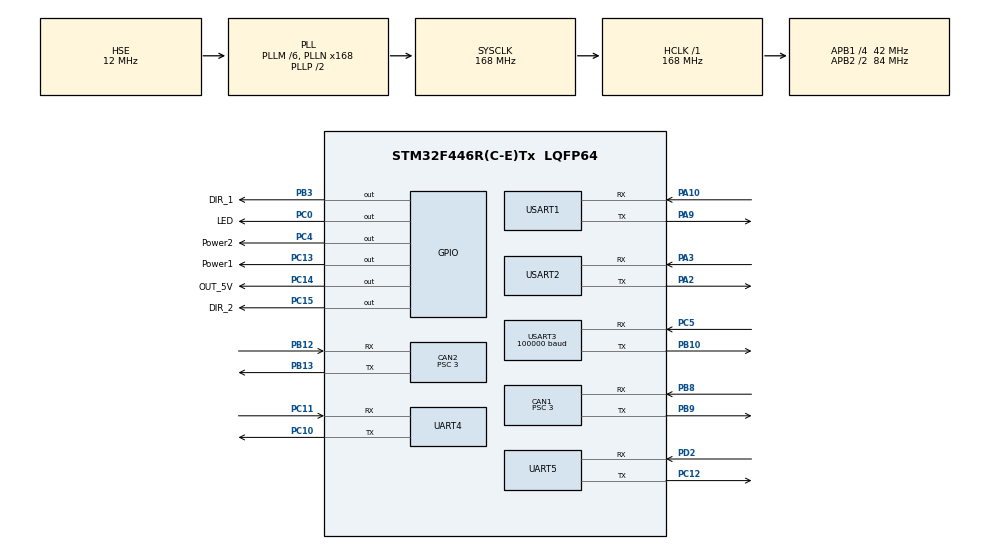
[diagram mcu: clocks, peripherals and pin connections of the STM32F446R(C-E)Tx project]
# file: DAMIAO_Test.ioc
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CAN1.BS1=CAN_BS1_10TQ
CAN1.BS2=CAN_BS2_3TQ
CAN1.CalculateBaudRate=1000000
CAN1.CalculateTimeBit=1000
CAN1.CalculateTimeQuantum=71.42857142857143
CAN1.Prescaler=3
CAN2.BS1=CAN_BS1_10TQ
CAN2.BS2=CAN_BS2_3TQ
CAN2.CalculateBaudRate=1000000
CAN2.CalculateTimeBit=1000
CAN2.CalculateTimeQuantum=71.42857142857143
CAN2.Prescaler=3
Dma.Request0=USART3_RX
Dma.Request1=USART3_TX
Dma.Request2=USART1_RX
Dma.Request3=USART1_TX
Dma.Request4=UART4_RX
Dma.Request5=UART4_TX
Dma.Request6=USART2_RX
Dma.Request7=USART2_TX
Dma.Request8=UART5_RX
Dma.Request9=UART5_TX
Dma.UART4_RX.4.Direction=DMA_PERIPH_TO_MEMORY
Dma.UART4_RX.4.FIFOMode=DMA_FIFOMODE_DISABLE
Dma.UART4_RX.4.Instance=DMA1_Stream2
Dma.UART4_RX.4.MemDataAlignment=DMA_MDATAALIGN_BYTE
Dma.UART4_RX.4.MemInc=DMA_MINC_ENABLE
Dma.UART4_RX.4.Mode=DMA_CIRCULAR
Dma.UART4_RX.4.PeriphDataAlignment=DMA_PDATAALIGN_BYTE
Dma.UART4_RX.4.PeriphInc=DMA_PINC_DISABLE
Dma.UART4_RX.4.Priority=DMA_PRIORITY_LOW
Dma.UART4_TX.5.Direction=DMA_MEMORY_TO_PERIPH
Dma.UART4_TX.5.FIFOMode=DMA_FIFOMODE_DISABLE
Dma.UART4_TX.5.Instance=DMA1_Stream4
Dma.UART4_TX.5.MemDataAlignment=DMA_MDATAALIGN_BYTE
Dma.UART4_TX.5.MemInc=DMA_MINC_ENABLE
Dma.UART4_TX.5.Mode=DMA_CIRCULAR
Dma.UART4_TX.5.PeriphDataAlignment=DMA_PDATAALIGN_BYTE
Dma.UART4_TX.5.PeriphInc=DMA_PINC_DISABLE
Dma.UART4_TX.5.Priority=DMA_PRIORITY_LOW
Dma.UART5_RX.8.Direction=DMA_PERIPH_TO_MEMORY
Dma.UART5_RX.8.FIFOMode=DMA_FIFOMODE_DISABLE
Dma.UART5_RX.8.Instance=DMA1_Stream0
Dma.UART5_RX.8.MemDataAlignment=DMA_MDATAALIGN_BYTE
Dma.UART5_RX.8.MemInc=DMA_MINC_ENABLE
Dma.UART5_RX.8.Mode=DMA_CIRCULAR
Dma.UART5_RX.8.PeriphDataAlignment=DMA_PDATAALIGN_BYTE
Dma.UART5_RX.8.PeriphInc=DMA_PINC_DISABLE
Dma.UART5_RX.8.Priority=DMA_PRIORITY_LOW
Dma.UART5_TX.9.Direction=DMA_MEMORY_TO_PERIPH
Dma.UART5_TX.9.FIFOMode=DMA_FIFOMODE_DISABLE
Dma.UART5_TX.9.Instance=DMA1_Stream7
Dma.UART5_TX.9.MemDataAlignment=DMA_MDATAALIGN_BYTE
Dma.UART5_TX.9.MemInc=DMA_MINC_ENABLE
Dma.UART5_TX.9.Mode=DMA_CIRCULAR
Dma.UART5_TX.9.PeriphDataAlignment=DMA_PDATAALIGN_BYTE
Dma.UART5_TX.9.PeriphInc=DMA_PINC_DISABLE
Dma.UART5_TX.9.Priority=DMA_PRIORITY_LOW
Dma.USART1_RX.2.Direction=DMA_PERIPH_TO_MEMORY
Dma.USART1_RX.2.FIFOMode=DMA_FIFOMODE_DISABLE
Dma.USART1_RX.2.Instance=DMA2_Stream5
Dma.USART1_RX.2.MemDataAlignment=DMA_MDATAALIGN_BYTE
Dma.USART1_RX.2.MemInc=DMA_MINC_ENABLE
Dma.USART1_RX.2.Mode=DMA_NORMAL
Dma.USART1_RX.2.PeriphDataAlignment=DMA_PDATAALIGN_BYTE
Dma.USART1_RX.2.PeriphInc=DMA_PINC_DISABLE
Dma.USART1_RX.2.Priority=DMA_PRIORITY_LOW
Dma.USART1_TX.3.Direction=DMA_MEMORY_TO_PERIPH
Dma.USART1_TX.3.FIFOMode=DMA_FIFOMODE_DISABLE
Dma.USART1_TX.3.Instance=DMA2_Stream7
Dma.USART1_TX.3.MemDataAlignment=DMA_MDATAALIGN_BYTE
Dma.USART1_TX.3.MemInc=DMA_MINC_ENABLE
Dma.USART1_TX.3.Mode=DMA_NORMAL
Dma.USART1_TX.3.PeriphDataAlignment=DMA_PDATAALIGN_BYTE
Dma.USART1_TX.3.PeriphInc=DMA_PINC_DISABLE
Dma.USART1_TX.3.Priority=DMA_PRIORITY_LOW
Dma.USART2_RX.6.Direction=DMA_PERIPH_TO_MEMORY
Dma.USART2_RX.6.FIFOMode=DMA_FIFOMODE_DISABLE
Dma.USART2_RX.6.Instance=DMA1_Stream5
Dma.USART2_RX.6.MemDataAlignment=DMA_MDATAALIGN_BYTE
Dma.USART2_RX.6.MemInc=DMA_MINC_ENABLE
Dma.USART2_RX.6.Mode=DMA_CIRCULAR
Dma.USART2_RX.6.PeriphDataAlignment=DMA_PDATAALIGN_BYTE
Dma.USART2_RX.6.PeriphInc=DMA_PINC_DISABLE
Dma.USART2_RX.6.Priority=DMA_PRIORITY_LOW
Dma.USART2_TX.7.Direction=DMA_MEMORY_TO_PERIPH
Dma.USART2_TX.7.FIFOMode=DMA_FIFOMODE_DISABLE
Dma.USART2_TX.7.Instance=DMA1_Stream6
Dma.USART2_TX.7.MemDataAlignment=DMA_MDATAALIGN_BYTE
Dma.USART2_TX.7.MemInc=DMA_MINC_ENABLE
Dma.USART2_TX.7.Mode=DMA_CIRCULAR
Dma.USART2_TX.7.PeriphDataAlignment=DMA_PDATAALIGN_BYTE
Dma.USART2_TX.7.PeriphInc=DMA_PINC_DISABLE
Dma.USART2_TX.7.Priority=DMA_PRIORITY_LOW
Dma.USART3_RX.0.Direction=DMA_PERIPH_TO_MEMORY
Dma.USART3_RX.0.FIFOMode=DMA_FIFOMODE_DISABLE
Dma.USART3_RX.0.Instance=DMA1_Stream1
Dma.USART3_RX.0.MemDataAlignment=DMA_MDATAALIGN_BYTE
Dma.USART3_RX.0.MemInc=DMA_MINC_ENABLE
Dma.USART3_RX.0.Mode=DMA_CIRCULAR
Dma.USART3_RX.0.PeriphDataAlignment=DMA_PDATAALIGN_BYTE
Dma.USART3_RX.0.PeriphInc=DMA_PINC_DISABLE
Dma.USART3_RX.0.Priority=DMA_PRIORITY_VERY_HIGH
Dma.USART3_TX.1.Direction=DMA_MEMORY_TO_PERIPH
Dma.USART3_TX.1.FIFOMode=DMA_FIFOMODE_DISABLE
Dma.USART3_TX.1.Instance=DMA1_Stream3
Dma.USART3_TX.1.MemDataAlignment=DMA_MDATAALIGN_BYTE
Dma.USART3_TX.1.MemInc=DMA_MINC_ENABLE
Dma.USART3_TX.1.Mode=DMA_NORMAL
Dma.USART3_TX.1.PeriphDataAlignment=DMA_PDATAALIGN_BYTE
Dma.USART3_TX.1.PeriphInc=DMA_PINC_DISABLE
Dma.USART3_TX.1.Priority=DMA_PRIORITY_VERY_HIGH
FREERTOS.Tasks01=defaultTask,0,128,StartDefaultTask,Default,NULL,Dynamic,NULL,NULL
Mcu.Family=STM32F4
Mcu.Name=STM32F446R(C-E)Tx
Mcu.Package=LQFP64
NVIC.CAN1_RX0_IRQn=true\:5\:0\:false\:false\:true\:true\:true\:true\:true
NVIC.CAN1_RX1_IRQn=true\:5\:0\:false\:false\:true\:true\:true\:true\:true
NVIC.CAN1_TX_IRQn=true\:5\:0\:false\:false\:true\:true\:true\:true\:true
NVIC.CAN2_RX0_IRQn=true\:5\:0\:false\:false\:true\:true\:true\:true\:true
NVIC.CAN2_RX1_IRQn=true\:5\:0\:false\:false\:true\:true\:true\:true\:true
NVIC.CAN2_TX_IRQn=true\:5\:0\:false\:false\:true\:true\:true\:true\:true
NVIC.DMA1_Stream0_IRQn=true\:5\:0\:false\:false\:true\:true\:false\:true\:true
NVIC.DMA1_Stream1_IRQn=true\:5\:0\:false\:false\:true\:true\:false\:true\:true
NVIC.DMA1_Stream2_IRQn=true\:5\:0\:false\:false\:true\:true\:false\:true\:true
NVIC.DMA1_Stream3_IRQn=true\:5\:0\:false\:false\:true\:true\:false\:true\:true
NVIC.DMA1_Stream4_IRQn=true\:5\:0\:false\:false\:true\:true\:false\:true\:true
NVIC.DMA1_Stream5_IRQn=true\:5\:0\:false\:false\:true\:true\:false\:true\:true
NVIC.DMA1_Stream6_IRQn=true\:5\:0\:false\:false\:true\:true\:false\:true\:true
NVIC.DMA1_Stream7_IRQn=true\:5\:0\:false\:false\:true\:true\:false\:true\:true
NVIC.DMA2_Stream5_IRQn=true\:5\:0\:false\:false\:true\:false\:false\:true\:true
NVIC.DMA2_Stream7_IRQn=true\:5\:0\:false\:false\:true\:true\:false\:true\:true
NVIC.PriorityGroup=NVIC_PRIORITYGROUP_4
NVIC.TIM8_TRG_COM_TIM14_IRQn=true\:15\:0\:false\:false\:true\:false\:false\:true\:true
NVIC.TimeBase=TIM8_TRG_COM_TIM14_IRQn
NVIC.TimeBaseIP=TIM14
NVIC.UART4_IRQn=true\:5\:0\:false\:false\:true\:true\:true\:true\:true
NVIC.UART5_IRQn=true\:5\:0\:false\:false\:true\:true\:true\:true\:true
NVIC.USART1_IRQn=true\:5\:0\:false\:false\:true\:true\:true\:true\:true
NVIC.USART2_IRQn=true\:5\:0\:false\:false\:true\:true\:true\:true\:true
NVIC.USART3_IRQn=true\:5\:0\:false\:false\:true\:true\:true\:true\:true
PA10.Mode=Asynchronous
PA10.Signal=USART1_RX
PA13.Mode=Serial_Wire
PA13.Signal=SYS_JTMS-SWDIO
PA14.Mode=Serial_Wire
PA14.Signal=SYS_JTCK-SWCLK
PA2.Mode=Asynchronous
PA2.Signal=USART2_TX
PA3.Mode=Asynchronous
PA3.Signal=USART2_RX
PA9.Mode=Asynchronous
PA9.Signal=USART1_TX
PB10.Mode=Asynchronous
PB10.Signal=USART3_TX
PB12.Mode=CAN_Activate
PB12.Signal=CAN2_RX
PB13.Mode=CAN_Activate
PB13.Signal=CAN2_TX
PB3.GPIO_Label=DIR_1
PB3.GPIO_PuPd=GPIO_PULLUP
PB3.Signal=GPIO_Output
PB8.Mode=CAN_Activate
PB8.Signal=CAN1_RX
PB9.Mode=CAN_Activate
PB9.Signal=CAN1_TX
PC0.GPIO_Label=LED
PC0.GPIO_PuPd=GPIO_PULLUP
PC0.PinState=GPIO_PIN_SET
PC0.Signal=GPIO_Output
PC10.Mode=Asynchronous
PC10.Signal=UART4_TX
PC11.Mode=Asynchronous
PC11.Signal=UART4_RX
PC12.Mode=Asynchronous
PC12.Signal=UART5_TX
PC13.GPIO_Label=Power1
PC13.GPIO_PuPd=GPIO_PULLUP
PC13.PinState=GPIO_PIN_SET
PC13.Signal=GPIO_Output
PC14-OSC32_IN.GPIO_Label=OUT_5V
PC14-OSC32_IN.GPIO_PuPd=GPIO_PULLUP
PC14-OSC32_IN.PinState=GPIO_PIN_SET
PC14-OSC32_IN.Signal=GPIO_Output
PC15-OSC32_OUT.GPIO_Label=DIR_2
PC15-OSC32_OUT.GPIO_PuPd=GPIO_PULLUP
PC15-OSC32_OUT.PinState=GPIO_PIN_RESET
PC15-OSC32_OUT.Signal=GPIO_Output
PC4.GPIO_Label=Power2
PC4.GPIO_PuPd=GPIO_PULLUP
PC4.PinState=GPIO_PIN_SET
PC4.Signal=GPIO_Output
PC5.Mode=Asynchronous
PC5.Signal=USART3_RX
PD2.Mode=Asynchronous
PD2.Signal=UART5_RX
PH0-OSC_IN.Mode=HSE-External-Oscillator
PH0-OSC_IN.Signal=RCC_OSC_IN
PH1-OSC_OUT.Mode=HSE-External-Oscillator
PH1-OSC_OUT.Signal=RCC_OSC_OUT
ProjectManager.HeapSize=0x200
ProjectManager.StackSize=0x400
ProjectManager.TargetToolchain=MDK-ARM V5.32
RCC.AHBFreq_Value=168000000
RCC.APB1CLKDivider=RCC_HCLK_DIV4
RCC.APB1Freq_Value=42000000
RCC.APB1TimFreq_Value=84000000
RCC.APB2CLKDivider=RCC_HCLK_DIV2
RCC.APB2Freq_Value=84000000
RCC.APB2TimFreq_Value=168000000
RCC.CortexFreq_Value=168000000
RCC.HCLKFreq_Value=168000000
RCC.HSE_VALUE=12000000
RCC.PLLM=6
RCC.PLLN=168
RCC.PLLSourceVirtual=RCC_PLLSOURCE_HSE
RCC.SYSCLKFreq_VALUE=168000000
RCC.SYSCLKSource=RCC_SYSCLKSOURCE_PLLCLK
RCC.USBFreq_Value=168000000
RCC.VCOOutputFreq_Value=336000000
UART4.VirtualMode=Asynchronous
UART5.VirtualMode=Asynchronous
USART1.VirtualMode=VM_ASYNC
USART2.VirtualMode=VM_ASYNC
USART3.BaudRate=100000
USART3.VirtualMode=VM_ASYNC
VP_FREERTOS_VS_CMSIS_V1.Mode=CMSIS_V1
VP_SYS_VS_tim14.Mode=TIM14
board=custom

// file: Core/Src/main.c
/* USER CODE BEGIN Header */
/**
  ******************************************************************************
  * @file           : main.c
  * @brief          : Main program body
  ******************************************************************************
  * @attention
  *
  * Copyright (c) 2024 STMicroelectronics.
  * All rights reserved.
  *
  * This software is licensed under terms that can be found in the LICENSE file
  * in the root directory of this software component.
  * If no LICENSE file comes with this software, it is provided AS-IS.
  *
  ******************************************************************************
  */
/* USER CODE END Header */
#include "main.h"
#include "cmsis_os.h"
#include "can.h"
#include "dma.h"
#include "usart.h"
#include "gpio.h"

/* USER CODE BEGIN Includes */
#include "Can_user.h"
#include "remote_control.h"
/* USER CODE END Includes */

void SystemClock_Config(void);
void MX_FREERTOS_Init(void);

/* USER CODE BEGIN 0 */
uint8_t Rx[128];
uint8_t Rx_R[128];
/* USER CODE END 0 */

int main(void)
{

  /* MCU Configuration--------------------------------------------------------*/

  /* Reset of all peripherals, Initializes the Flash interface and the Systick. */
  HAL_Init();

  /* Configure the system clock */
  SystemClock_Config();

  /* Initialize all configured peripherals */
  MX_GPIO_Init();
  MX_DMA_Init();
  MX_CAN1_Init();
  MX_CAN2_Init();
  MX_USART3_UART_Init();
  MX_USART1_UART_Init();
  MX_USART2_UART_Init();
  MX_UART4_Init();
  MX_UART5_Init();
  /* USER CODE BEGIN 2 */
	can_1_user_init(&hcan1);//配置can1的过滤器
	can_2_user_init(&hcan2);//配置can2的过滤器
	remote_control_init(); //遥控器初始化

	__HAL_UART_ENABLE_IT(&huart2,UART_IT_IDLE);
	HAL_UART_Receive_DMA(&huart2,(uint8_t *)Rx,sizeof(Rx)); //陀螺仪接收中断

	__HAL_UART_ENABLE_IT(&huart5,UART_IT_IDLE);
	HAL_UART_Receive_DMA(&huart5,(uint8_t *)Rx_R,sizeof(Rx_R));
  /* USER CODE END 2 */

  /* Call init function for freertos objects (in freertos.c) */
  MX_FREERTOS_Init();

  /* Start scheduler */
  osKernelStart();

  /* We should never get here as control is now taken by the scheduler */
  /* Infinite loop */
  while (1)
  {

  }
}

void SystemClock_Config(void)
{
  RCC_OscInitTypeDef RCC_OscInitStruct = {0};
  RCC_ClkInitTypeDef RCC_ClkInitStruct = {0};

  /** Configure the main internal regulator output voltage
  */
  __HAL_RCC_PWR_CLK_ENABLE();
  __HAL_PWR_VOLTAGESCALING_CONFIG(PWR_REGULATOR_VOLTAGE_SCALE1);

  /** Initializes the RCC Oscillators according to the specified parameters
  * in the RCC_OscInitTypeDef structure.
  */
  RCC_OscInitStruct.OscillatorType = RCC_OSCILLATORTYPE_HSE;
  RCC_OscInitStruct.HSEState = RCC_HSE_ON;
  RCC_OscInitStruct.PLL.PLLState = RCC_PLL_ON;
  RCC_OscInitStruct.PLL.PLLSource = RCC_PLLSOURCE_HSE;
  RCC_OscInitStruct.PLL.PLLM = 6;
  RCC_OscInitStruct.PLL.PLLN = 168;
  RCC_OscInitStruct.PLL.PLLP = RCC_PLLP_DIV2;
  RCC_OscInitStruct.PLL.PLLQ = 2;
  RCC_OscInitStruct.PLL.PLLR = 2;
  if (HAL_RCC_OscConfig(&RCC_OscInitStruct) != HAL_OK)
  {
    Error_Handler();
  }

  /** Initializes the CPU, AHB and APB buses clocks
  */
  RCC_ClkInitStruct.ClockType = RCC_CLOCKTYPE_HCLK|RCC_CLOCKTYPE_SYSCLK
                              |RCC_CLOCKTYPE_PCLK1|RCC_CLOCKTYPE_PCLK2;
  RCC_ClkInitStruct.SYSCLKSource = RCC_SYSCLKSOURCE_PLLCLK;
  RCC_ClkInitStruct.AHBCLKDivider = RCC_SYSCLK_DIV1;
  RCC_ClkInitStruct.APB1CLKDivider = RCC_HCLK_DIV4;
  RCC_ClkInitStruct.APB2CLKDivider = RCC_HCLK_DIV2;

  if (HAL_RCC_ClockConfig(&RCC_ClkInitStruct, FLASH_LATENCY_5) != HAL_OK)
  {
    Error_Handler();
  }
}

void HAL_TIM_PeriodElapsedCallback(TIM_HandleTypeDef *htim)
{
  if (htim->Instance == TIM14) {
    HAL_IncTick();
  }
}

void Error_Handler(void)
{
  __disable_irq();
  while (1)
  {
  }
}
